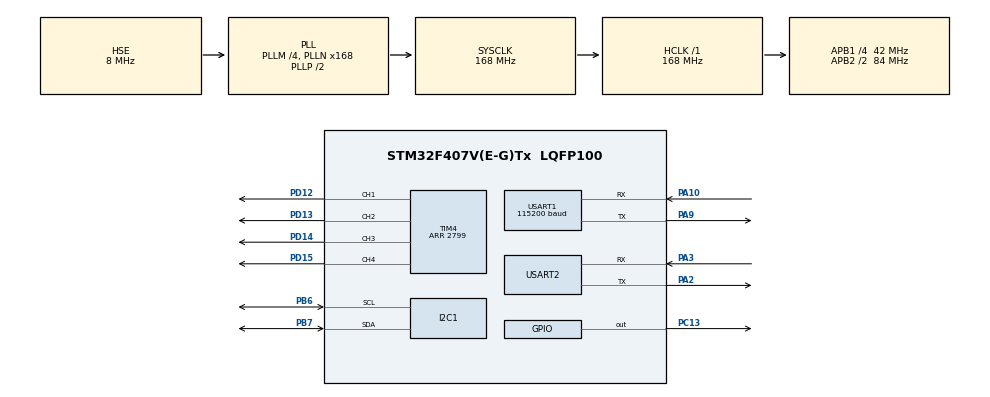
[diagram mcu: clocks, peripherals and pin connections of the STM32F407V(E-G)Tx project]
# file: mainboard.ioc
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Dma.I2C1_RX.4.Direction=DMA_PERIPH_TO_MEMORY
Dma.I2C1_RX.4.FIFOMode=DMA_FIFOMODE_DISABLE
Dma.I2C1_RX.4.Instance=DMA1_Stream0
Dma.I2C1_RX.4.MemDataAlignment=DMA_MDATAALIGN_BYTE
Dma.I2C1_RX.4.MemInc=DMA_MINC_ENABLE
Dma.I2C1_RX.4.Mode=DMA_NORMAL
Dma.I2C1_RX.4.PeriphDataAlignment=DMA_PDATAALIGN_BYTE
Dma.I2C1_RX.4.PeriphInc=DMA_PINC_DISABLE
Dma.I2C1_RX.4.Priority=DMA_PRIORITY_HIGH
Dma.I2C1_TX.5.Direction=DMA_MEMORY_TO_PERIPH
Dma.I2C1_TX.5.FIFOMode=DMA_FIFOMODE_DISABLE
Dma.I2C1_TX.5.Instance=DMA1_Stream7
Dma.I2C1_TX.5.MemDataAlignment=DMA_MDATAALIGN_BYTE
Dma.I2C1_TX.5.MemInc=DMA_MINC_ENABLE
Dma.I2C1_TX.5.Mode=DMA_NORMAL
Dma.I2C1_TX.5.PeriphDataAlignment=DMA_PDATAALIGN_BYTE
Dma.I2C1_TX.5.PeriphInc=DMA_PINC_DISABLE
Dma.I2C1_TX.5.Priority=DMA_PRIORITY_HIGH
Dma.Request0=USART1_RX
Dma.Request1=USART1_TX
Dma.Request2=USART2_RX
Dma.Request3=USART2_TX
Dma.Request4=I2C1_RX
Dma.Request5=I2C1_TX
Dma.USART1_RX.0.Direction=DMA_PERIPH_TO_MEMORY
Dma.USART1_RX.0.FIFOMode=DMA_FIFOMODE_DISABLE
Dma.USART1_RX.0.Instance=DMA2_Stream2
Dma.USART1_RX.0.MemDataAlignment=DMA_MDATAALIGN_BYTE
Dma.USART1_RX.0.MemInc=DMA_MINC_ENABLE
Dma.USART1_RX.0.Mode=DMA_NORMAL
Dma.USART1_RX.0.PeriphDataAlignment=DMA_PDATAALIGN_BYTE
Dma.USART1_RX.0.PeriphInc=DMA_PINC_DISABLE
Dma.USART1_RX.0.Priority=DMA_PRIORITY_LOW
Dma.USART1_TX.1.Direction=DMA_MEMORY_TO_PERIPH
Dma.USART1_TX.1.FIFOMode=DMA_FIFOMODE_DISABLE
Dma.USART1_TX.1.Instance=DMA2_Stream7
Dma.USART1_TX.1.MemDataAlignment=DMA_MDATAALIGN_BYTE
Dma.USART1_TX.1.MemInc=DMA_MINC_ENABLE
Dma.USART1_TX.1.Mode=DMA_NORMAL
Dma.USART1_TX.1.PeriphDataAlignment=DMA_PDATAALIGN_BYTE
Dma.USART1_TX.1.PeriphInc=DMA_PINC_DISABLE
Dma.USART1_TX.1.Priority=DMA_PRIORITY_LOW
Dma.USART2_RX.2.Direction=DMA_PERIPH_TO_MEMORY
Dma.USART2_RX.2.FIFOMode=DMA_FIFOMODE_DISABLE
Dma.USART2_RX.2.Instance=DMA1_Stream5
Dma.USART2_RX.2.MemDataAlignment=DMA_MDATAALIGN_BYTE
Dma.USART2_RX.2.MemInc=DMA_MINC_ENABLE
Dma.USART2_RX.2.Mode=DMA_CIRCULAR
Dma.USART2_RX.2.PeriphDataAlignment=DMA_PDATAALIGN_BYTE
Dma.USART2_RX.2.PeriphInc=DMA_PINC_DISABLE
Dma.USART2_RX.2.Priority=DMA_PRIORITY_HIGH
Dma.USART2_TX.3.Direction=DMA_MEMORY_TO_PERIPH
Dma.USART2_TX.3.FIFOMode=DMA_FIFOMODE_DISABLE
Dma.USART2_TX.3.Instance=DMA1_Stream6
Dma.USART2_TX.3.MemDataAlignment=DMA_MDATAALIGN_BYTE
Dma.USART2_TX.3.MemInc=DMA_MINC_ENABLE
Dma.USART2_TX.3.Mode=DMA_NORMAL
Dma.USART2_TX.3.PeriphDataAlignment=DMA_PDATAALIGN_BYTE
Dma.USART2_TX.3.PeriphInc=DMA_PINC_DISABLE
Dma.USART2_TX.3.Priority=DMA_PRIORITY_MEDIUM
FREERTOS.INCLUDE_vTaskDelayUntil=1
FREERTOS.INCLUDE_xTaskGetCurrentTaskHandle=1
FREERTOS.Tasks01=defaultTask,0,128,StartDefaultTask,Default,NULL,Dynamic,NULL,NULL
I2C1.I2C_Mode=I2C_Fast
I2C1.OwnAddress=0x0A
Mcu.Family=STM32F4
Mcu.Name=STM32F407V(E-G)Tx
Mcu.Package=LQFP100
NVIC.DMA1_Stream0_IRQn=true\:5\:0\:true\:false\:true\:false\:false\:true
NVIC.DMA1_Stream5_IRQn=true\:6\:0\:true\:false\:false\:true\:false\:false
NVIC.DMA1_Stream6_IRQn=true\:6\:0\:true\:false\:false\:true\:false\:false
NVIC.DMA1_Stream7_IRQn=true\:5\:0\:true\:false\:true\:false\:false\:true
NVIC.DMA2_Stream2_IRQn=true\:10\:0\:true\:false\:true\:true\:false\:true
NVIC.DMA2_Stream7_IRQn=true\:10\:0\:true\:false\:true\:true\:false\:true
NVIC.I2C1_ER_IRQn=true\:5\:0\:true\:false\:true\:false\:true\:true
NVIC.I2C1_EV_IRQn=true\:5\:0\:true\:false\:true\:true\:true\:true
NVIC.PriorityGroup=NVIC_PRIORITYGROUP_4
NVIC.TIM7_IRQn=true\:0\:0\:false\:false\:true\:false\:false\:true
NVIC.TimeBase=TIM7_IRQn
NVIC.TimeBaseIP=TIM7
NVIC.USART1_IRQn=true\:10\:0\:true\:false\:true\:true\:true\:true
NVIC.USART2_IRQn=true\:6\:0\:true\:false\:false\:true\:true\:false
PA10.Mode=Asynchronous
PA10.Signal=USART1_RX
PA13.Mode=Serial_Wire
PA13.Signal=SYS_JTMS-SWDIO
PA14.Mode=Serial_Wire
PA14.Signal=SYS_JTCK-SWCLK
PA2.Mode=Asynchronous
PA2.Signal=USART2_TX
PA3.Mode=Asynchronous
PA3.Signal=USART2_RX
PA9.Mode=Asynchronous
PA9.Signal=USART1_TX
PB6.GPIO_PuPdOD=GPIO_NOPULL
PB6.Mode=I2C
PB6.Signal=I2C1_SCL
PB7.GPIO_PuPdOD=GPIO_NOPULL
PB7.Mode=I2C
PB7.Signal=I2C1_SDA
PC13-ANTI_TAMP.GPIO_ModeDefaultOutputPP=GPIO_MODE_OUTPUT_PP
PC13-ANTI_TAMP.GPIO_PuPd=GPIO_PULLUP
PC13-ANTI_TAMP.PinState=GPIO_PIN_SET
PC13-ANTI_TAMP.Signal=GPIO_Output
PC14-OSC32_IN.Mode=LSE-External-Oscillator
PC14-OSC32_IN.Signal=RCC_OSC32_IN
PC15-OSC32_OUT.Mode=LSE-External-Oscillator
PC15-OSC32_OUT.Signal=RCC_OSC32_OUT
PD12.Signal=S_TIM4_CH1
PD13.Signal=S_TIM4_CH2
PD14.Signal=S_TIM4_CH3
PD15.Signal=S_TIM4_CH4
PH0-OSC_IN.Mode=HSE-External-Oscillator
PH0-OSC_IN.Signal=RCC_OSC_IN
PH1-OSC_OUT.Mode=HSE-External-Oscillator
PH1-OSC_OUT.Signal=RCC_OSC_OUT
ProjectManager.HeapSize=0x200
ProjectManager.StackSize=0x400
ProjectManager.TargetToolchain=Makefile
RCC.48MHZClocksFreq_Value=84000000
RCC.AHBFreq_Value=168000000
RCC.APB1CLKDivider=RCC_HCLK_DIV4
RCC.APB1Freq_Value=42000000
RCC.APB1TimFreq_Value=84000000
RCC.APB2CLKDivider=RCC_HCLK_DIV2
RCC.APB2Freq_Value=84000000
RCC.APB2TimFreq_Value=168000000
RCC.CortexFreq_Value=168000000
RCC.HCLKFreq_Value=168000000
RCC.HSE_VALUE=8000000
RCC.HSI_VALUE=16000000
RCC.PLLM=4
RCC.PLLN=168
RCC.PLLSourceVirtual=RCC_PLLSOURCE_HSE
RCC.SYSCLKFreq_VALUE=168000000
RCC.SYSCLKSource=RCC_SYSCLKSOURCE_PLLCLK
RCC.VCOOutputFreq_Value=336000000
SH.S_TIM4_CH1.0=TIM4_CH1,PWM Generation1 CH1
SH.S_TIM4_CH2.0=TIM4_CH2,PWM Generation2 CH2
SH.S_TIM4_CH3.0=TIM4_CH3,PWM Generation3 CH3
SH.S_TIM4_CH4.0=TIM4_CH4,PWM Generation4 CH4
TIM4.Channel-PWM\ Generation1\ CH1=TIM_CHANNEL_1
TIM4.Channel-PWM\ Generation2\ CH2=TIM_CHANNEL_2
TIM4.Channel-PWM\ Generation3\ CH3=TIM_CHANNEL_3
TIM4.Channel-PWM\ Generation4\ CH4=TIM_CHANNEL_4
TIM4.Period=2799
USART1.BaudRate=115200
USART1.VirtualMode=VM_ASYNC
USART2.VirtualMode=VM_ASYNC
VP_FREERTOS_VS_CMSIS_V1.Mode=CMSIS_V1
VP_SYS_VS_tim7.Mode=TIM7
VP_TIM4_VS_ClockSourceINT.Mode=Internal
board=custom

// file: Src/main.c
/* USER CODE BEGIN Header */
/**
  ******************************************************************************
  * @file           : main.c
  * @brief          : Main program body
  ******************************************************************************
  * @attention
  *
  * <h2><center>&copy; Copyright (c) 2020 STMicroelectronics.
  * All rights reserved.</center></h2>
  *
  * This software component is licensed by ST under Ultimate Liberty license
  * SLA0044, the "License"; You may not use this file except in compliance with
  * the License. You may obtain a copy of the License at:
  *                             www.st.com/SLA0044
  *
  ******************************************************************************
  */
/* USER CODE END Header */
#include "main.h"
#include "cmsis_os.h"
#include "dma.h"
#include "i2c.h"
#include "tim.h"
#include "usart.h"
#include "gpio.h"

/* USER CODE BEGIN Includes */
// #include "uart4.h"
// #include "mavlink_task.h"
// #include "sensors.h"
// #include "dmp.h"
// #include "ms5611.h"
// #include "mpu6050.h"
// #include "i2c1.h"
// #include "gy_86.h"
#include "system_task.h"

#ifdef USE_SISTEMVEIW
#include "systemview_task.h"
#endif
/* USER CODE END Includes */

void SystemClock_Config(void);
void MX_FREERTOS_Init(void);

int main(void)
{

  /* MCU Configuration--------------------------------------------------------*/

  /* Reset of all peripherals, Initializes the Flash interface and the Systick. */
  HAL_Init();

  /* Configure the system clock */
  SystemClock_Config();

  /* USER CODE BEGIN SysInit */
  // __HAL_RCC_I2C1_CLK_ENABLE();
  // __HAL_RCC_DMA1_CLK_ENABLE();

  /* USER CODE END SysInit */

  /* Initialize all configured peripherals */
  MX_GPIO_Init();
  MX_DMA_Init();
  MX_USART1_UART_Init();
  MX_TIM4_Init();
  MX_USART2_UART_Init();
  MX_I2C1_Init();
  /* USER CODE BEGIN 2 */

#ifdef USE_SISTEMVEIW
  SystemViewLaunch();
#endif

  SystemLaunch();

  // SensorsInit();
  // MavlinkInit();

  // MotorInit();
  // TestI2C1MenRead();
  // MS5611Init();
  // I2C1Init();
  // bool flag = MPU6050Init();
  // printf("status:%u\r\n", flag);
  // float ax, ay, az;
  // Uart4Init();

  // uint8_t buffer[] = "Hello world\r\n";
  // HAL_UART_Transmit_DMA(&huart1, buffer, sizeof(buffer));

  /* USER CODE END 2 */

  /* Call init function for freertos objects (in freertos.c) */
  MX_FREERTOS_Init();
  /* Start scheduler */
  osKernelStart();

  /* We should never get here as control is now taken by the scheduler */
  /* Infinite loop */
  while (1)
  {

    /* USER CODE BEGIN 3 */

    // MPU6050ReadAccel(&ax, &ay, &az);
    // printf("%f\r\n", 3.1415926);
    // printf("%f, %f, %f \r\n", ax, ay, az);
    // HAL_Delay(1000);
    // HAL_UART_Transmit_DMA(&huart4, buffer, sizeof(buffer));
    // HAL_UART_Transmit_DMA(&huart1, buffer, sizeof(buffer));
    // printf("%d ok1\r\n", 10);
    // HAL_Delay(10);
    // printf("%d ok2\r\n", 10);
    // HAL_Delay(10);
    // printf("%d ok3\r\n", 10);
    // HAL_Delay(1000);
  }
  /* USER CODE END 3 */
}

void SystemClock_Config(void)
{
  RCC_OscInitTypeDef RCC_OscInitStruct = {0};
  RCC_ClkInitTypeDef RCC_ClkInitStruct = {0};

  /** Configure the main internal regulator output voltage
  */
  __HAL_RCC_PWR_CLK_ENABLE();
  __HAL_PWR_VOLTAGESCALING_CONFIG(PWR_REGULATOR_VOLTAGE_SCALE1);
  /** Initializes the RCC Oscillators according to the specified parameters
  * in the RCC_OscInitTypeDef structure.
  */
  RCC_OscInitStruct.OscillatorType = RCC_OSCILLATORTYPE_HSE;
  RCC_OscInitStruct.HSEState = RCC_HSE_ON;
  RCC_OscInitStruct.PLL.PLLState = RCC_PLL_ON;
  RCC_OscInitStruct.PLL.PLLSource = RCC_PLLSOURCE_HSE;
  RCC_OscInitStruct.PLL.PLLM = 4;
  RCC_OscInitStruct.PLL.PLLN = 168;
  RCC_OscInitStruct.PLL.PLLP = RCC_PLLP_DIV2;
  RCC_OscInitStruct.PLL.PLLQ = 4;
  if (HAL_RCC_OscConfig(&RCC_OscInitStruct) != HAL_OK)
  {
    Error_Handler();
  }
  /** Initializes the CPU, AHB and APB buses clocks
  */
  RCC_ClkInitStruct.ClockType = RCC_CLOCKTYPE_HCLK|RCC_CLOCKTYPE_SYSCLK
                              |RCC_CLOCKTYPE_PCLK1|RCC_CLOCKTYPE_PCLK2;
  RCC_ClkInitStruct.SYSCLKSource = RCC_SYSCLKSOURCE_PLLCLK;
  RCC_ClkInitStruct.AHBCLKDivider = RCC_SYSCLK_DIV1;
  RCC_ClkInitStruct.APB1CLKDivider = RCC_HCLK_DIV4;
  RCC_ClkInitStruct.APB2CLKDivider = RCC_HCLK_DIV2;

  if (HAL_RCC_ClockConfig(&RCC_ClkInitStruct, FLASH_LATENCY_5) != HAL_OK)
  {
    Error_Handler();
  }
}

 /**
  * @brief  Period elapsed callback in non blocking mode
  * @note   This function is called  when TIM7 interrupt took place, inside
  * HAL_TIM_IRQHandler(). It makes a direct call to HAL_IncTick() to increment
  * a global variable "uwTick" used as application time base.
  * @param  htim : TIM handle
  * @retval None
  */
void HAL_TIM_PeriodElapsedCallback(TIM_HandleTypeDef *htim)
{
  if (htim->Instance == TIM7) {
    HAL_IncTick();
  }
}

void Error_Handler(void)
{
}

/************************ (C) COPYRIGHT STMicroelectronics *****END OF FILE****/

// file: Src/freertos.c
/* USER CODE BEGIN Header */
/**
  ******************************************************************************
  * File Name          : freertos.c
  * Description        : Code for freertos applications
  ******************************************************************************
  * @attention
  *
  * <h2><center>&copy; Copyright (c) 2020 STMicroelectronics.
  * All rights reserved.</center></h2>
  *
  * This software component is licensed by ST under Ultimate Liberty license
  * SLA0044, the "License"; You may not use this file except in compliance with
  * the License. You may obtain a copy of the License at:
  *                             www.st.com/SLA0044
  *
  ******************************************************************************
  */
/* USER CODE END Header */

#include "FreeRTOS.h"
#include "task.h"
#include "main.h"
#include "cmsis_os.h"

osThreadId defaultTaskHandle;

void StartDefaultTask(void const * argument);

void MX_FREERTOS_Init(void); /* (MISRA C 2004 rule 8.1) */

/* GetIdleTaskMemory prototype (linked to static allocation support) */
void vApplicationGetIdleTaskMemory( StaticTask_t **ppxIdleTaskTCBBuffer, StackType_t **ppxIdleTaskStackBuffer, uint32_t *pulIdleTaskStackSize );

/* USER CODE BEGIN GET_IDLE_TASK_MEMORY */
static StaticTask_t xIdleTaskTCBBuffer;
static StackType_t xIdleStack[configMINIMAL_STACK_SIZE];

void vApplicationGetIdleTaskMemory( StaticTask_t **ppxIdleTaskTCBBuffer, StackType_t **ppxIdleTaskStackBuffer, uint32_t *pulIdleTaskStackSize )
{
  *ppxIdleTaskTCBBuffer = &xIdleTaskTCBBuffer;
  *ppxIdleTaskStackBuffer = &xIdleStack[0];
  *pulIdleTaskStackSize = configMINIMAL_STACK_SIZE;
  /* place for user code */
}
/* USER CODE END GET_IDLE_TASK_MEMORY */

void MX_FREERTOS_Init(void) {

  /* Create the thread(s) */
  /* definition and creation of defaultTask */
  osThreadDef(defaultTask, StartDefaultTask, osPriorityNormal, 0, 128);
  defaultTaskHandle = osThreadCreate(osThread(defaultTask), NULL);

}

void StartDefaultTask(void const * argument)
{
  for(;;)
  {
    osDelay(1);
  }
}

/************************ (C) COPYRIGHT STMicroelectronics *****END OF FILE****/
